# fcr_me14 register map
Registers are read-write, no defined reset value unless marked. A register's access mark holds for its fields unless they carry their own. Offsets are from the block's base; lines under a group give offsets from that group; [hi:lo] are bit positions; {n}, {i} and the like mark numbered series; 'fields as' and 'values as' point back to an identical list; <NAME> marks a mode.

## Memory map
0x40000800 FCR size 0x400 — Function Control.

## FCR — Function Control.
Base 0x40000800
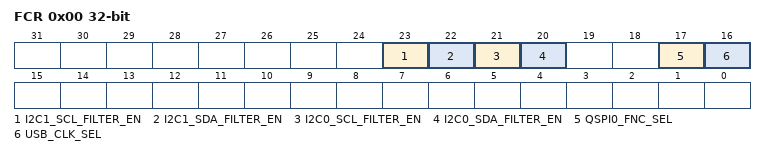
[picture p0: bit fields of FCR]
0x00 FCR — Register 0.
  [23] I2C1_SCL_FILTER_EN — I2C1 SCL Pad Deglitcher enable.
    0=dis (Deglitcher disabled.); 1=en (Deglitcher enabled.)
  [22] I2C1_SDA_FILTER_EN — I2C1 SDA Pad Deglitcher enable.
    0=dis (Deglitcher disabled.); 1=en (Deglitcher enabled.)
  [21] I2C0_SCL_FILTER_EN — I2C0 SCL Pad Deglitcher enable.
    0=dis (Deglitcher disabled.); 1=en (Deglitcher enabled.)
  [20] I2C0_SDA_FILTER_EN — I2C0 SDA Pad Deglitcher enable.
    0=dis (Deglitcher disabled.); 1=en (Deglitcher enabled.)
  [17] QSPI0_FNC_SEL — SPI0 Function Select.
    0=hirc (High speed 96MHz oscillator.); 1=ext_clk (External clock input.)
  [16] USB_CLK_SEL — USB External Core Clock Select.
    0=sys (Generated clock from system clock.); 1=dig (Digital clock from a GPIO.)
